# MSP430F5529 register map
Vendor: msp430gen; File version: v0.4.0-10-gd4db4bc
Registers are 8-bit, read-write, reset 0x0 unless marked. A register's access mark holds for its fields unless they carry their own. Offsets are from the block's base; lines under a group give offsets from that group; [hi:lo] are bit positions; {n}, {i} and the like mark numbered series; 'fields as' and 'values as' point back to an identical list; <NAME> marks a mode.

## Memory map
0x00000100 SFR — SFR Special Function Registers
0x00000120 PMM — PMM Power Management System
0x00000140 FLASH
0x00000150 CRC16
0x00000158 RC — RC RAM Control Module
0x0000015C WATCHDOG_TIMER
0x00000160 UCS — UCS Unified System Clock
0x00000180 SYS — SYS System Module
0x000001B0 SHARED_REFERENCE
0x000001C0 PORT_MAPPING_CONTROL
0x000001E0 PORT_MAPPING_PORT_4
0x00000200 PORT_1_2
0x00000220 PORT_3_4
0x00000240 PORT_5_6
0x00000260 PORT_7_8
0x00000320 PORT_J
0x00000340 TIMER0_A5 — Timer A5
0x00000380 TIMER1_A3 — Timer A3
0x000003C0 TIMER_0_B7
0x00000400 TIMER2_A3 — Timer A3
0x000004A0 RTC — RTC Real Time Clock
0x000004C0 MPY_16 — MPY 16 Multiplier 16 Bit Mode
0x000004D0 MPY_32 — MPY 32 Multiplier 32 Bit Mode
0x00000500 DMA
0x000005C0 USCI_A0_UART_MODE
0x000005C0 USCI_A0_SPI_MODE
0x000005E0 USCI_B0_I2C_MODE
0x000005E0 USCI_B0_SPI_MODE
0x00000600 USCI_A1_UART_MODE
0x00000600 USCI_A1_SPI_MODE
0x00000620 USCI_B1_I2C_MODE
0x00000620 USCI_B1_SPI_MODE
0x00000700 ADC12
0x000008C0 COMPARATOR_B
0x00000900 USB_CONTROL
0x00001C00 USB_OPERATION
0x0000FF80 _INTERRUPTS

## Interrupts
41 RTC (_INTERRUPTS) — 0xFFD2 RTC
42 PORT2 (_INTERRUPTS) — 0xFFD4 Port 2
43 TIMER2_A1 (_INTERRUPTS) — 0xFFD6 Timer2_A5 CC1-4, TA
44 TIMER2_A0 (_INTERRUPTS) — 0xFFD8 Timer2_A5 CC0
45 USCI_B1 (_INTERRUPTS) — 0xFFDA USCI B1 Receive/Transmit
46 USCI_A1 (_INTERRUPTS) — 0xFFDC USCI A1 Receive/Transmit
47 PORT1 (_INTERRUPTS) — 0xFFDE Port 1
48 TIMER1_A1 (_INTERRUPTS) — 0xFFE0 Timer1_A3 CC1-2, TA1
49 TIMER1_A0 (_INTERRUPTS) — 0xFFE2 Timer1_A3 CC0
50 DMA (_INTERRUPTS) — 0xFFE4 DMA
51 USB_UBM (_INTERRUPTS) — 0xFFE6 USB Timer / cable event / USB reset
52 TIMER0_A1 (_INTERRUPTS) — 0xFFE8 Timer0_A5 CC1-4, TA
53 TIMER0_A0 (_INTERRUPTS) — 0xFFEA Timer0_A5 CC0
54 ADC12 (_INTERRUPTS) — 0xFFEC ADC
55 USCI_B0 (_INTERRUPTS) — 0xFFEE USCI B0 Receive/Transmit
56 USCI_A0 (_INTERRUPTS) — 0xFFF0 USCI A0 Receive/Transmit
57 WDT (_INTERRUPTS) — 0xFFF2 Watchdog Timer
58 TIMER0_B1 (_INTERRUPTS) — 0xFFF4 Timer0_B7 CC1-6, TB
59 TIMER0_B0 (_INTERRUPTS) — 0xFFF6 Timer0_B7 CC0
60 COMP_B (_INTERRUPTS) — 0xFFF8 Comparator B
61 UNMI (_INTERRUPTS) — 0xFFFA User Non-maskable
62 SYSNMI (_INTERRUPTS) — 0xFFFC System Non-maskable

## PORT_MAPPING_PORT_4
Base 0x000001E0
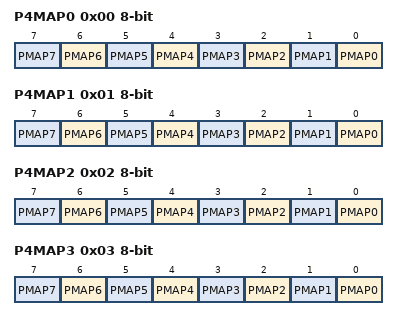
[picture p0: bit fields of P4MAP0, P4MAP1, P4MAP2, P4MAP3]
0x00 P4MAP0 — Port P4.0 mapping register
  [n] PMAP{n} (n=0..7)
0x01 P4MAP1 — Port P4.1 mapping register
  [n] PMAP{n} (n=0..7)
0x02 P4MAP2 — Port P4.2 mapping register
  [n] PMAP{n} (n=0..7)
0x03 P4MAP3 — Port P4.3 mapping register
  [n] PMAP{n} (n=0..7)
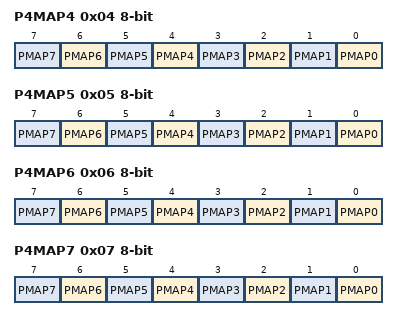
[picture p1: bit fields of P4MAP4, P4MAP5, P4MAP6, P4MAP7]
0x04 P4MAP4 — Port P4.4 mapping register
  [n] PMAP{n} (n=0..7)
0x05 P4MAP5 — Port P4.5 mapping register
  [n] PMAP{n} (n=0..7)
0x06 P4MAP6 — Port P4.6 mapping register
  [n] PMAP{n} (n=0..7)
0x07 P4MAP7 — Port P4.7 mapping register
  [n] PMAP{n} (n=0..7)

## PORT_1_2
Base 0x00000200
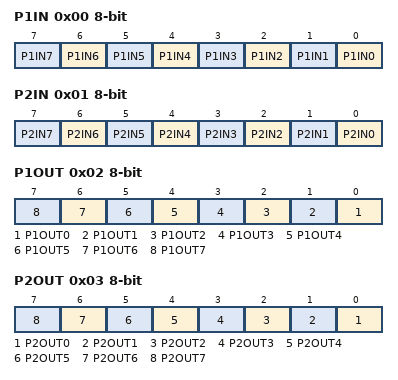
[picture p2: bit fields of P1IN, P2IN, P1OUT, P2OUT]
0x00 P1IN — Port 1 Input
  [n] P1IN{n} (n=0..7)
0x01 P2IN — Port 2 Input
  [n] P2IN{n} (n=0..7)
0x02 P1OUT — Port 1 Output
  [n] P1OUT{n} (n=0..7)
0x03 P2OUT — Port 2 Output
  [n] P2OUT{n} (n=0..7)
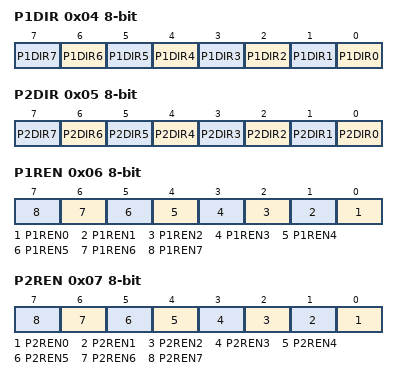
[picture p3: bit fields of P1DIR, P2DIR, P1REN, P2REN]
0x04 P1DIR — Port 1 Direction
  [n] P1DIR{n} (n=0..7)
0x05 P2DIR — Port 2 Direction
  [n] P2DIR{n} (n=0..7)
0x06 P1REN — Port 1 Resistor Enable
  [n] P1REN{n} (n=0..7)
0x07 P2REN — Port 2 Resistor Enable
  [n] P2REN{n} (n=0..7)
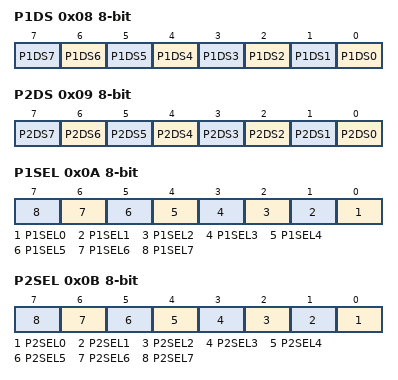
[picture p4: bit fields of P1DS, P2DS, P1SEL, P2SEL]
0x08 P1DS — Port 1 Drive Strenght
  [n] P1DS{n} (n=0..7)
0x09 P2DS — Port 2 Drive Strenght
  [n] P2DS{n} (n=0..7)
0x0A P1SEL — Port 1 Selection
  [n] P1SEL{n} (n=0..7)
0x0B P2SEL — Port 2 Selection
  [n] P2SEL{n} (n=0..7)
0x0E P1IV 16-bit — Port 1 Interrupt Vector Word
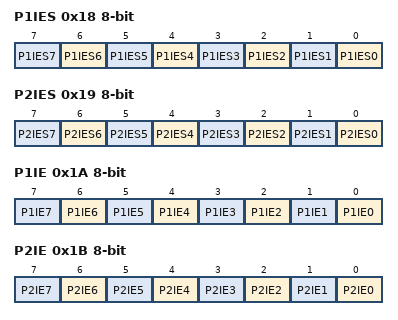
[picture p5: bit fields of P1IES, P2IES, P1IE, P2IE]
0x18 P1IES — Port 1 Interrupt Edge Select
  [n] P1IES{n} (n=0..7)
0x19 P2IES — Port 2 Interrupt Edge Select
  [n] P2IES{n} (n=0..7)
0x1A P1IE — Port 1 Interrupt Enable
  [n] P1IE{n} (n=0..7)
0x1B P2IE — Port 2 Interrupt Enable
  [n] P2IE{n} (n=0..7)
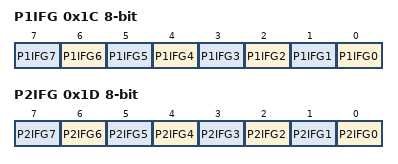
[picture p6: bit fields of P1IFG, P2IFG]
0x1C P1IFG — Port 1 Interrupt Flag
  [n] P1IFG{n} (n=0..7)
0x1D P2IFG — Port 2 Interrupt Flag
  [n] P2IFG{n} (n=0..7)
0x1E P2IV 16-bit — Port 2 Interrupt Vector Word
